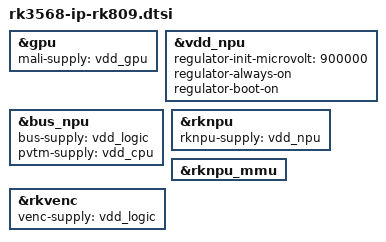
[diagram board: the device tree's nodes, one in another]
&gpu {
	mali-supply = <&vdd_gpu>;
	status = "okay";
};

&vdd_npu {
	regulator-init-microvolt = <900000>;
	regulator-always-on;
	regulator-boot-on;
};

&bus_npu {
	bus-supply = <&vdd_logic>;
	pvtm-supply = <&vdd_cpu>;
	status = "okay";
};

&rknpu {
	rknpu-supply = <&vdd_npu>;
	status = "okay";
};

&rknpu_mmu {
	status = "okay";
};


&rkvenc {
	venc-supply = <&vdd_logic>;
	status = "okay";
};
